# SIM3U164_B register map
File version: 1
CPU: 
Registers are 32-bit, read-write, reset 0x0 unless marked. A register's access mark holds for its fields unless they carry their own. Offsets are from the block's base; [hi:lo] are bit positions; {n}, {i} and the like mark numbered series.

## LPOSC_0
Base 0x40041000
0x00 OSCVAL reset 0x8 — Low Power Oscillator Output Value
  [3:0] OSCVAL ro — Low Power Oscillator Output Value.

## PBSTD_0
Base 0x4002A0A0
Same registers: PBSTD_1 0x4002A140
0x00 PB reset 0xFFFF — Output Latch
  [15:0] PB — Output Latch.
0x10 PBPIN — Pin Value
  [15:0] PBPIN ro — Pin Value.
0x20 PBMDSEL reset 0xFFFF — Mode Select
  [15:0] PBMDSEL — Mode Select.
0x30 PBSKIPEN — Crossbar Pin Skip Enable
  [15:0] PBSKIPEN — Crossbar Pin Skip Enable.
0x40 PBOUTMD — Output Mode
  [15:0] PBOUTMD — Output Mode.
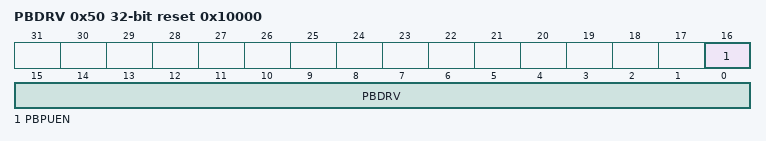
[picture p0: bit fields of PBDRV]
0x50 PBDRV reset 0x10000 — Drive Strength
  [16] PBPUEN — Port Bank Weak Pull-up Enable.
    0=DISABLED (Disable weak pull-ups for this port.); 1=ENABLED (Enable weak pull-ups for this port.)
  [15:0] PBDRV — Drive Strength.
0x60 PM — Port Match Value
  [15:0] PM — Port Match Value.
0x70 PMEN — Port Match Enable
  [15:0] PMEN — Port Match Enable.

## PBSTD_2
Base 0x4002A1E0
Registers as PBSTD_0; these are added or differ:
0x80 PBLOCK — Lock Control
  [15:0] PBLOCK — Port Bank Lock.
0x90 PBPGEN — Pulse Generator Pin Enable
  [15:0] PBPGEN — Pulse Generator Pin Enable.
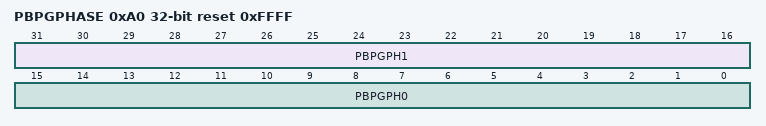
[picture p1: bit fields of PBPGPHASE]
0xA0 PBPGPHASE reset 0xFFFF — Pulse Generator Phase
  [31:16] PBPGPH1 — Pulse Generator Phase 1.
  [15:0] PBPGPH0 — Pulse Generator Phase 0.

## PBSTD_3
Base 0x4002A320
Registers as PBSTD_2, without PBPGEN, PBPGPHASE.

## SSG_0
Base 0x4001E000
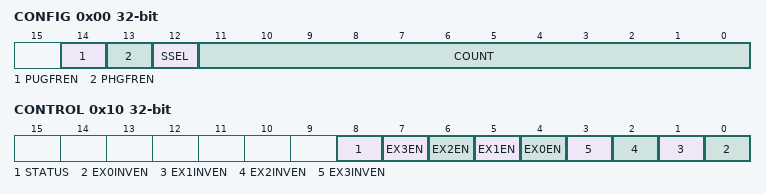
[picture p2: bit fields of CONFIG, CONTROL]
0x00 CONFIG — Module Configuration
  [14] PUGFREN — Pulse Generator Free-Run Enable.
    0=DISABLED (The COUNT field determines the number of pulses generated by the Pulse Generator.); 1=ENABLED (The Pulse Generator always generates pulses regardless of COUNT unless all outputs are disabled (EX0EN, EX1EN, EX2EN, and EX3EN are all 0).)
  [13] PHGFREN — Phase Generator Free-Run Enable.
    0=DISABLED (The Phase Generator runs only when pulse generation occurs.); 1=ENABLED (The Phase Generator runs when an ADC is enabled, regardless of the Pulse Generator settings.)
  [12] SSEL — Speed Select.
    0=NORMAL (The SSG module runs at normal speed, where each pulse and phase cycle consists of 16 ADC clocks.); 1=DOUBLE (The SSG module runs at double speed, where each pulse and phase cycle consists of 8 ADC clocks.)
  [11:0] COUNT — Pulse Generator Counter.
0x10 CONTROL — Module Control
  [8] STATUS ro — SSG Module Status.
    0=IDLE (The SSG module is idle and the Pulse Generator is not operating.); 1=ACTIVE (The SSG module is active and the Pulse Generator is counting.)
  [n+4] EX{n}EN (n=0..3) — Output {n} Enable.
    0=DISABLED (Disable the EX{n} Pulse Generator output.); 1=ENABLED (Enable the EX{n} Pulse Generator output.)
  [n] EX{n}INVEN (n=0..3) — Output {n} Invert Enable.
    0=NORMAL (Do not invert the Pulse Generator output on EX{n}.); 1=INVERT (Invert the Pulse Generator output on EX{n}.)

## VMON_0
Base 0x4002F000
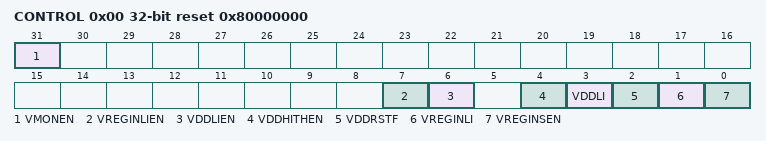
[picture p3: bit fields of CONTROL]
0x00 CONTROL reset 0x80000000 — Module Control
  [31] VMONEN — VDD Supply Monitor Enable.
    0=DISABLED (Disable the VDD supply monitor.); 1=ENABLED (Enable the VDD supply monitor.)
  [7] VREGINLIEN — VREGIN Low Interrupt Enable.
    0=DISABLED (Disable the VREGIN low interrupt.); 1=ENABLED (Enable the VREGIN low interrupt.)
  [6] VDDLIEN — VDD Low Interrupt Enable.
    0=DISABLED (Disable the VDD low interrupt.); 1=ENABLED (Enable the VDD low interrupt.)
  [4] VDDHITHEN — VDD High Threshold Enable.
    0=DISABLED (Use the standard VDD thresholds.); 1=ENABLED (Use the high VDD thresholds.)
  [3] VDDLI ro — VDD Low Interrupt Flag.
    0=VDD_IS_LOW (The VDD voltage is below the early warning threshold.); 1=VDD_IS_OK (The VDD voltage is above the early warning threshold.)
  [2] VDDRSTF ro — VDD Reset Threshold Status Flag.
    0=VDD_IS_BELOW_RESET (The VDD voltage is below the VDD reset threshold.); 1=VDD_IS_ABOVE_RESET (The VDD voltage is above the VDD reset threshold.)
  [1] VREGINLI ro — VREGIN Low Interrupt Flag.
    0=VREGIN_IS_LOW (VREGIN is not above the interrupt threshold.); 1=VREGIN_IS_OK (VREGIN is above the interrupt threshold.)
  [0] VREGINSEN — VREGIN Supply Monitor Enable.
    0=DISABLED (Disable the VREGIN supply monitor.); 1=ENABLED (Enable the VREGIN supply monitor.)
